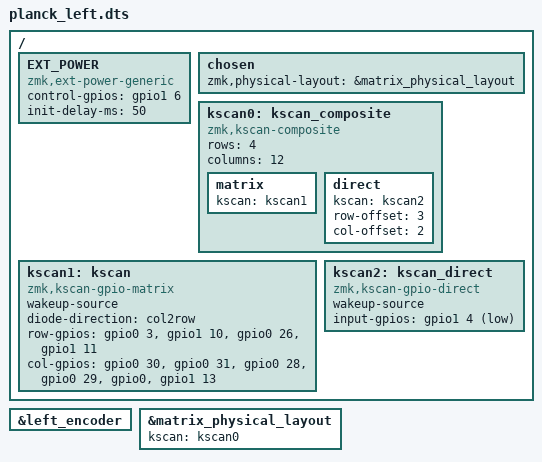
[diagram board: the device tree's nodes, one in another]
#include "planck.dtsi"
#include <dt-bindings/led/led.h>
#include "leds.dtsi"

/ {
	EXT_POWER {
		compatible = "zmk,ext-power-generic";
		control-gpios = <&gpio1 6 GPIO_ACTIVE_HIGH>;
		init-delay-ms = <50>;
	};
};

&left_encoder {
    status = "okay";
};

&matrix_physical_layout {
  	kscan = <&kscan0>;
};

/ {
	chosen {
		zmk,physical-layout = &matrix_physical_layout;
	};
		kscan0: kscan_composite {
        compatible = "zmk,kscan-composite";
        rows = <4>;
        columns = <12>;

        // Include the matrix driver
        matrix {
            kscan = <&kscan1>;
        };

        // Include the direct GPIO driver...
        direct {
            kscan = <&kscan2>;
						row-offset=<3>;
            col-offset = <2>; // ...and shift it to not overlap
        };
    };
    kscan1: kscan {
        compatible = "zmk,kscan-gpio-matrix";
        wakeup-source;

        diode-direction = "col2row";
        row-gpios
            = <&gpio0 3 (GPIO_ACTIVE_HIGH | GPIO_PULL_DOWN)>
            , <&gpio1 10 (GPIO_ACTIVE_HIGH | GPIO_PULL_DOWN)>
            , <&gpio0 26  (GPIO_ACTIVE_HIGH | GPIO_PULL_DOWN)>
            , <&gpio1 11 (GPIO_ACTIVE_HIGH | GPIO_PULL_DOWN)>
            ;

    col-gpios
           = <&gpio0 30 (GPIO_ACTIVE_HIGH)>
            , <&gpio0  31  (GPIO_ACTIVE_HIGH)>
            , <&gpio0 28 (GPIO_ACTIVE_HIGH)>
            , <&gpio0 29 (GPIO_ACTIVE_HIGH)>
            , <&gpio0  2(GPIO_ACTIVE_HIGH)>
            , <&gpio1 13 (GPIO_ACTIVE_HIGH)>;
     
    };
	 kscan2: kscan_direct {
        compatible = "zmk,kscan-gpio-direct";
				wakeup-source;
				input-gpios = 
							<&gpio1 4 (GPIO_ACTIVE_LOW | GPIO_PULL_UP)>;
    };
};
